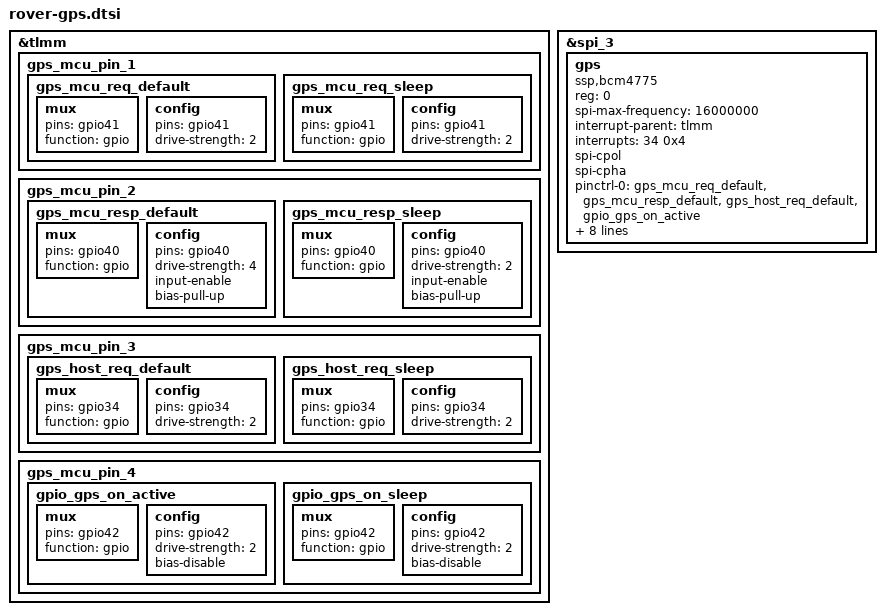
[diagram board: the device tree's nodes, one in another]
&tlmm{
	gps_mcu_pin_1{
		gps_mcu_req_default:gps_mcu_req_default{
		mux{
			pins="gpio41";
			function="gpio";
			};
		config{
			pins="gpio41";
			drive-strength=<2>;/*2MA*/
			};
		};
		gps_mcu_req_sleep:gps_mcu_req_sleep{
		mux{
			pins="gpio41";
			function="gpio";
			};
		config{
			pins="gpio41";
			drive-strength=<2>;/*2MA*/
			};
		};
	};
	gps_mcu_pin_2{
		gps_mcu_resp_default:gps_mcu_resp_default{
		mux{
			pins="gpio40";
			function="gpio";
			};
		config{
			pins="gpio40";
			drive-strength=<4>;/*2MA*/
			input-enable;
			bias-pull-up;
			};
		};
		gps_mcu_resp_sleep:gps_mcu_resp_sleep{
		mux{
			pins="gpio40";
			function="gpio";
			};
		config{
			pins="gpio40";
			drive-strength=<2>;/*2MA*/
			input-enable;
			bias-pull-up;
			};
		};
	};
	gps_mcu_pin_3{
		gps_host_req_default:gps_host_req_default{
			mux{
			pins="gpio34";
			function="gpio";
			};
			config{
			pins="gpio34";
			drive-strength=<2>;/*2MA*/
			};
		};
		gps_host_req_sleep:gps_host_req_sleep{
		mux{
			pins="gpio34";
			function="gpio";
			};
		config{
			pins="gpio34";
			drive-strength=<2>;/*2MA*/
			};
		};
	};
	gps_mcu_pin_4{
		gpio_gps_on_active:gpio_gps_on_active{
		mux{
			pins="gpio42";
			function="gpio";
			};
		config{
			pins="gpio42";
			drive-strength=<2>;
			bias-disable;
			};
		};
		gpio_gps_on_sleep:gpio_gps_on_sleep{
		mux{
			pins="gpio42";
			function="gpio";
			};
		config{
			pins="gpio42";
			drive-strength=<2>;
			bias-disable;
			};
		};
	};
};

&spi_3{
	gps{
		compatible="ssp,bcm4775";
		reg=<0>;
		spi-max-frequency=<16000000>;
		interrupt-parent=<&tlmm>;
		interrupts=<34 0x4>;
		spi-cpol;
		spi-cpha;
		pinctrl-names="default","sleep";
		pinctrl-0=<&gps_mcu_req_default &gps_mcu_resp_default
				&gps_host_req_default &gpio_gps_on_active>;
		pinctrl-1=<&gps_mcu_req_sleep &gps_mcu_resp_sleep
				&gps_host_req_sleep &gpio_gps_on_sleep>;
		ssp-host-req=<&tlmm 34 0x4>;
		ssp-mcu-req=<&tlmm 41 0>;
		ssp-mcu-resp=<&tlmm 40 0>;
		power_enable=<&tlmm 43 0>;
		ssp-nstandby=<&tlmm 42 0>;
		status="ok";
	};
};
